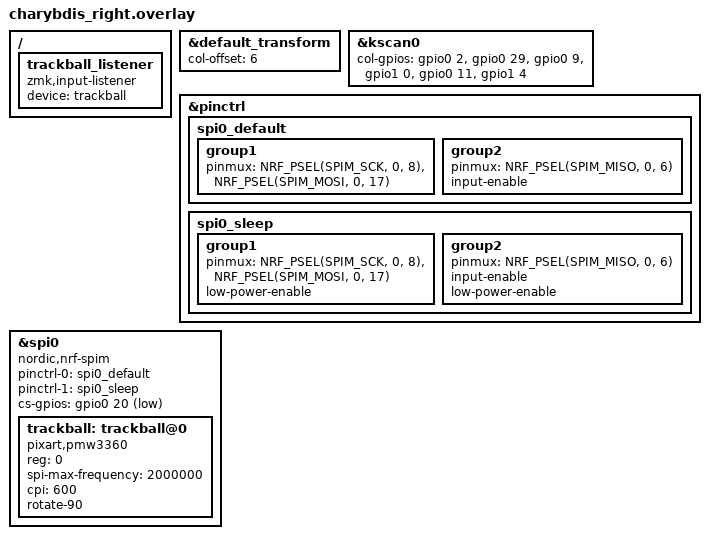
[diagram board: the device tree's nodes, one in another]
#include "charybdis.dtsi"

&default_transform {
    col-offset = <6>;
};

&kscan0 {
    col-gpios
        = <&gpio0 2  (GPIO_ACTIVE_HIGH | GPIO_PULL_DOWN)>
        , <&gpio0 29 (GPIO_ACTIVE_HIGH | GPIO_PULL_DOWN)>
        , <&gpio0 9  (GPIO_ACTIVE_HIGH | GPIO_PULL_DOWN)>
        , <&gpio1 0  (GPIO_ACTIVE_HIGH | GPIO_PULL_DOWN)>
        , <&gpio0 11 (GPIO_ACTIVE_HIGH | GPIO_PULL_DOWN)>
        , <&gpio1 4  (GPIO_ACTIVE_HIGH | GPIO_PULL_DOWN)>
        ;
};

&pinctrl {
    spi0_default: spi0_default {
        group1 {
            pinmux = <NRF_PSEL(SPIM_SCK, 0, 8)>,
                     <NRF_PSEL(SPIM_MOSI, 0, 17)>;
        };
        group2 {
            pinmux = <NRF_PSEL(SPIM_MISO, 0, 6)>;
            input-enable;
        };
    };

    spi0_sleep: spi0_sleep {
        group1 {
            pinmux = <NRF_PSEL(SPIM_SCK, 0, 8)>,
                     <NRF_PSEL(SPIM_MOSI, 0, 17)>;
            low-power-enable;
        };
        group2 {
            pinmux = <NRF_PSEL(SPIM_MISO, 0, 6)>;
            input-enable;
            low-power-enable;
        };
    };
};

&spi0 {
    status = "okay";
    compatible = "nordic,nrf-spim";
    pinctrl-0 = <&spi0_default>;
    pinctrl-1 = <&spi0_sleep>;
    pinctrl-names = "default", "sleep";
    cs-gpios = <&gpio0 20 GPIO_ACTIVE_LOW>;

    trackball: trackball@0 {
        compatible = "pixart,pmw3360";
        status = "okay";
        reg = <0>;
        spi-max-frequency = <2000000>;
        cpi = <600>;
        rotate-90;
    };
};

/ {
    trackball_listener {
        compatible = "zmk,input-listener";
        device = <&trackball>;
    };
};
